VERSION ""

NS_ :

BS_:

BU_: XXX

BO_ 3 STEERING: 8 XXX
 SG_ STEERING_ANGLE : 3|12@0- (0.03,0) [-30|30] "degree" XXX

BO_ 5 BRAKE: 8 XXX
 SG_ BRAKE_PRESSED : 0|8@0+ (1,0) [0|0] "" XXX
 SG_ BRAKE_POSITION : 19|12@0+ (1,0) [0|4095] "" XXX

BO_ 261 GAS: 8 XXX
 SG_ RPM : 7|16@0+ (1,0) [0|255] "" XXX
 SG_ GAS : 31|8@0+ (1,0) [0|255] "" XXX

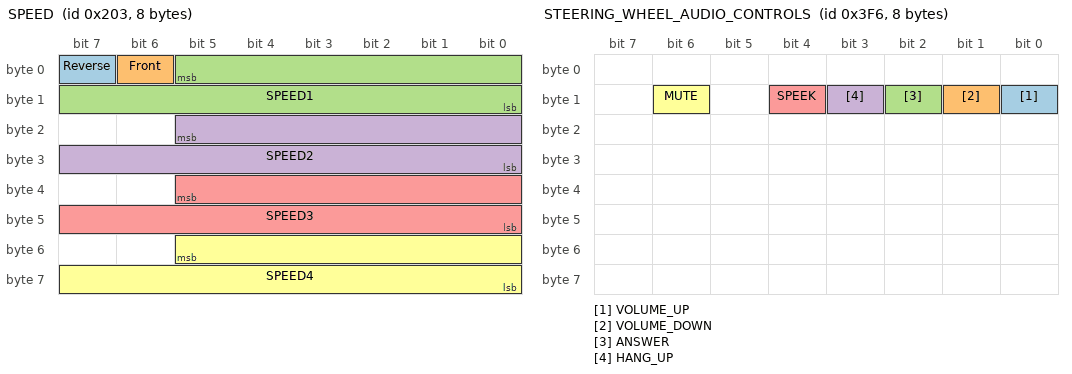
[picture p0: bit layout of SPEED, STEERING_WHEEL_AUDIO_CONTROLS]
BO_ 515 SPEED: 8 XXX
 SG_ Reverse : 7|1@0+ (1,0) [0|1] "" XXX
 SG_ Front : 6|1@0+ (1,0) [0|1] "" XXX
 SG_ SPEED1 : 5|14@0+ (1,0) [0|16383] "" XXX
 SG_ SPEED2 : 21|14@0+ (1,0) [0|255] "" XXX
 SG_ SPEED3 : 37|14@0+ (1,0) [0|16383] "" XXX
 SG_ SPEED4 : 53|14@0+ (1,0) [0|16383] "" XXX

BO_ 1014 STEERING_WHEEL_AUDIO_CONTROLS: 8 XXX
 SG_ VOLUME_UP : 8|1@1+ (1,0) [0|1] "" XXX
 SG_ VOLUME_DOWN : 9|1@0+ (1,0) [0|1] "" XXX
 SG_ ANSWER : 10|1@0+ (1,0) [0|1] "" XXX
 SG_ HANG_UP : 11|1@0+ (1,0) [0|1] "" XXX
 SG_ SPEEK : 12|1@0+ (1,0) [0|1] "" XXX
 SG_ MUTE : 14|1@0+ (1,0) [0|1] "" XXX
